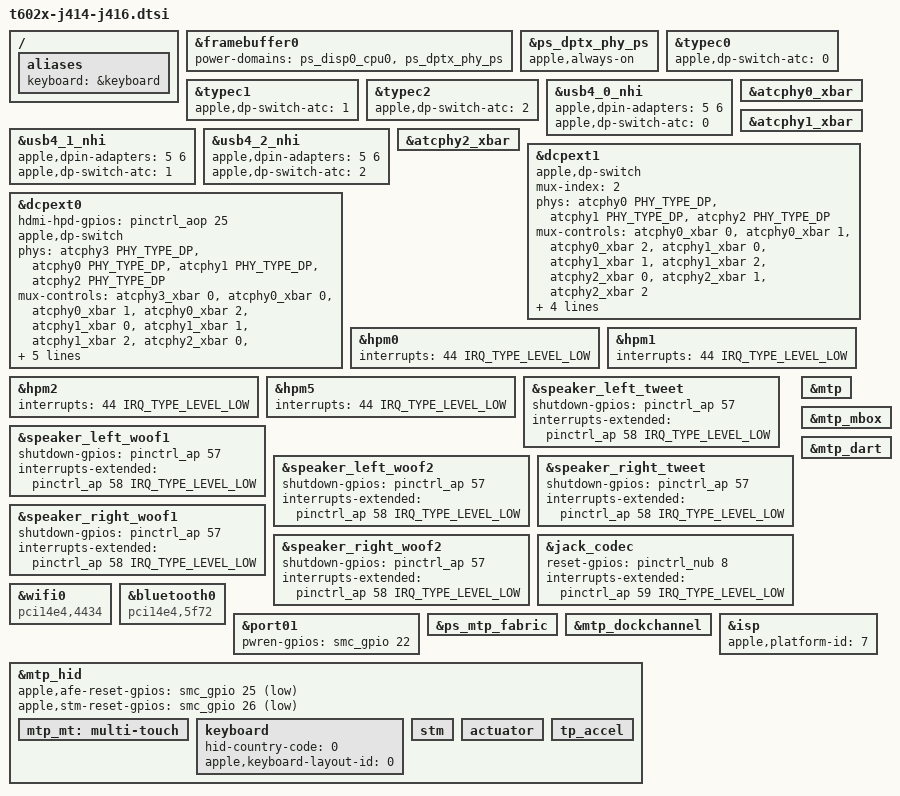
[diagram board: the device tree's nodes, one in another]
// SPDX-License-Identifier: GPL-2.0+ OR MIT
/*
 * MacBook Pro (14/16-inch, 2022)
 *
 * This file contains the parts common to J414 and J416 devices with both t6020 and t6021.
 *
 * target-type: J414s / J414c / J416s / J416c
 *
 * Copyright The Asahi Linux Contributors
 */

/*
 * These models are essentially identical to the previous generation, other than
 * the GPIO indices.
 */

#define NO_SPI_TRACKPAD
#include "t600x-j314-j316.dtsi"

/ {
	aliases {
		keyboard = &keyboard;
	};
};

&framebuffer0 {
	power-domains = <&ps_disp0_cpu0>, <&ps_dptx_phy_ps>;
};

/* HACK: keep dptx_phy_ps power-domain always-on
 *       it is unclear how to sequence with dcp for the integrated display
 */
&ps_dptx_phy_ps {
	apple,always-on;
};

/*
 * Display switch: the Type-C ports' DP PHYs (DP alt mode) and their host
 * routers' DP IN adapters (DP tunnelled over USB4), handed out to a DCP when
 * a sink shows up there, as macOS does.
 */
&typec0 {
	apple,dp-switch-atc = <0>;
};

&typec1 {
	/delete-property/ displayport;
	apple,dp-switch-atc = <1>;
};

&typec2 {
	apple,dp-switch-atc = <2>;
};

&usb4_0_nhi {
	apple,dpin-adapters = <5 6>;
	apple,dp-switch-atc = <0>;
};

&usb4_1_nhi {
	apple,dpin-adapters = <5 6>;
	apple,dp-switch-atc = <1>;
};

&usb4_2_nhi {
	apple,dpin-adapters = <5 6>;
	apple,dp-switch-atc = <2>;
};

&atcphy0_xbar {
	status = "okay";
};

&atcphy1_xbar {
	status = "okay";
};

&atcphy2_xbar {
	status = "okay";
};

&dcpext1 {
	/delete-property/ apple,dptx-phy;
	apple,dp-switch;
	/* dispext1 */
	mux-index = <2>;
	phys = <&atcphy0 PHY_TYPE_DP>, <&atcphy1 PHY_TYPE_DP>,
		<&atcphy2 PHY_TYPE_DP>;
	phy-names = "atc0", "atc1", "atc2";
	mux-controls = <&atcphy0_xbar 0>, <&atcphy0_xbar 1>, <&atcphy0_xbar 2>,
		<&atcphy1_xbar 0>, <&atcphy1_xbar 1>, <&atcphy1_xbar 2>,
		<&atcphy2_xbar 0>, <&atcphy2_xbar 1>, <&atcphy2_xbar 2>;
	mux-control-names = "atc0-dpphy", "atc0-dpin0", "atc0-dpin1",
		"atc1-dpphy", "atc1-dpin0", "atc1-dpin1",
		"atc2-dpphy", "atc2-dpin0", "atc2-dpin1";
};

&dcpext0 {
	/*  HDMI HPD gpio, used as interrupt*/
	hdmi-hpd-gpios = <&pinctrl_aop 25 GPIO_ACTIVE_HIGH>;

	/* with HDMI empty it also serves the display switch, as dispext0 */
	apple,dp-switch;
	phys = <&atcphy3 PHY_TYPE_DP>, <&atcphy0 PHY_TYPE_DP>,
		<&atcphy1 PHY_TYPE_DP>, <&atcphy2 PHY_TYPE_DP>;
	phy-names = "dp-phy", "atc0", "atc1", "atc2";
	mux-controls = <&atcphy3_xbar 0>,
		<&atcphy0_xbar 0>, <&atcphy0_xbar 1>, <&atcphy0_xbar 2>,
		<&atcphy1_xbar 0>, <&atcphy1_xbar 1>, <&atcphy1_xbar 2>,
		<&atcphy2_xbar 0>, <&atcphy2_xbar 1>, <&atcphy2_xbar 2>;
	mux-control-names = "dp-xbar",
		"atc0-dpphy", "atc0-dpin0", "atc0-dpin1",
		"atc1-dpphy", "atc1-dpin0", "atc1-dpin1",
		"atc2-dpphy", "atc2-dpin0", "atc2-dpin1";
};

&hpm0 {
	interrupts = <44 IRQ_TYPE_LEVEL_LOW>;
};

&hpm1 {
	interrupts = <44 IRQ_TYPE_LEVEL_LOW>;
};

&hpm2 {
	interrupts = <44 IRQ_TYPE_LEVEL_LOW>;
};

&hpm5 {
	interrupts = <44 IRQ_TYPE_LEVEL_LOW>;
};

&speaker_left_tweet {
	shutdown-gpios = <&pinctrl_ap 57 GPIO_ACTIVE_HIGH>;
	interrupts-extended = <&pinctrl_ap 58 IRQ_TYPE_LEVEL_LOW>;
};

&speaker_left_woof1 {
	shutdown-gpios = <&pinctrl_ap 57 GPIO_ACTIVE_HIGH>;
	interrupts-extended = <&pinctrl_ap 58 IRQ_TYPE_LEVEL_LOW>;
};

&speaker_left_woof2 {
	shutdown-gpios = <&pinctrl_ap 57 GPIO_ACTIVE_HIGH>;
	interrupts-extended = <&pinctrl_ap 58 IRQ_TYPE_LEVEL_LOW>;
};

&speaker_right_tweet {
	shutdown-gpios = <&pinctrl_ap 57 GPIO_ACTIVE_HIGH>;
	interrupts-extended = <&pinctrl_ap 58 IRQ_TYPE_LEVEL_LOW>;
};

&speaker_right_woof1 {
	shutdown-gpios = <&pinctrl_ap 57 GPIO_ACTIVE_HIGH>;
	interrupts-extended = <&pinctrl_ap 58 IRQ_TYPE_LEVEL_LOW>;
};

&speaker_right_woof2 {
	shutdown-gpios = <&pinctrl_ap 57 GPIO_ACTIVE_HIGH>;
	interrupts-extended = <&pinctrl_ap 58 IRQ_TYPE_LEVEL_LOW>;
};

&jack_codec {
	reset-gpios = <&pinctrl_nub 8 GPIO_ACTIVE_HIGH>;
	interrupts-extended = <&pinctrl_ap 59 IRQ_TYPE_LEVEL_LOW>;
};

&wifi0 {
	compatible = "pci14e4,4434";
};

&bluetooth0 {
	compatible = "pci14e4,5f72";
};

&port01 {
	pwren-gpios = <&smc_gpio 22 GPIO_ACTIVE_HIGH>;
};

&ps_mtp_fabric {
	status = "okay";
};

&mtp {
	status = "okay";
};

&mtp_mbox {
	status = "okay";
};

&mtp_dart {
	status = "okay";
};

&mtp_dockchannel {
	status = "okay";
};

&mtp_hid {
	apple,afe-reset-gpios = <&smc_gpio 25 GPIO_ACTIVE_LOW>;
	apple,stm-reset-gpios = <&smc_gpio 26 GPIO_ACTIVE_LOW>;

	mtp_mt: multi-touch {
	};

	keyboard: keyboard {
		hid-country-code = <0>;
		apple,keyboard-layout-id = <0>;
	};

	stm {
	};

	actuator {
	};

	tp_accel {
	};
};

&isp {
	apple,platform-id = <7>;
	/delete-node/ sensor-presets; /* Override j31[46] below */
};

#include "isp-imx558-cfg0.dtsi"
